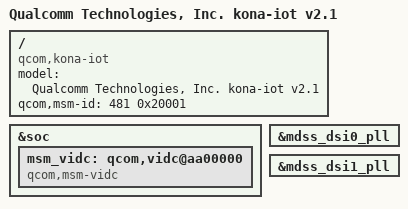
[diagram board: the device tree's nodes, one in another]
 #include "kona-v2.1.dtsi"

/ {
	model = "Qualcomm Technologies, Inc. kona-iot v2.1";
	compatible = "qcom,kona-iot";
	qcom,msm-id = <481 0x20001>;
};

&soc {
	msm_vidc: qcom,vidc@aa00000 {
		compatible = "qcom,msm-vidc", "qcom,qcs8250-vidc";
	};
};

&mdss_dsi0_pll {
	/delete-property/ qcom,dsi-pll-ssc-en;
	/delete-property/ qcom,dsi-pll-ssc-mode;
};

&mdss_dsi1_pll {
	/delete-property/ qcom,dsi-pll-ssc-en;
	/delete-property/ qcom,dsi-pll-ssc-mode;
};
